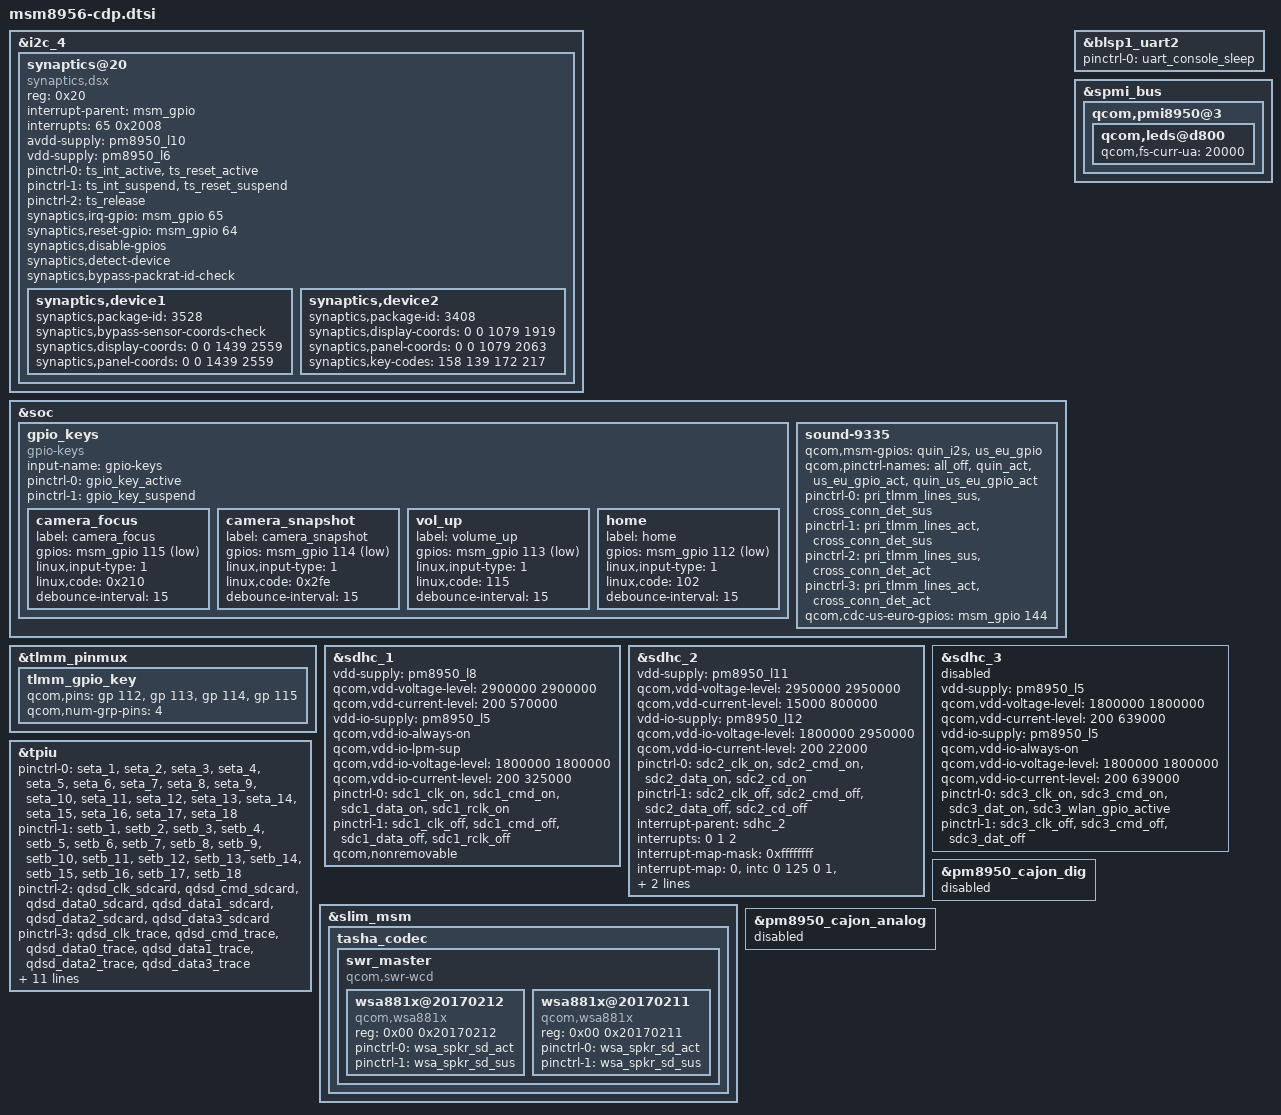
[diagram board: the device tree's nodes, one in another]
/*
 * Copyright (c) 2015, The Linux Foundation. All rights reserved.
 *
 * This program is free software; you can redistribute it and/or modify
 * it under the terms of the GNU General Public License version 2 and
 * only version 2 as published by the Free Software Foundation.
 *
 * This program is distributed in the hope that it will be useful,
 * but WITHOUT ANY WARRANTY; without even the implied warranty of
 * MERCHANTABILITY or FITNESS FOR A PARTICULAR PURPOSE.  See the
 * GNU General Public License for more details.
 */

#include "msm8976-pinctrl.dtsi"
#include "msm8976-camera-sensor-cdp.dtsi"
#include "msm8976-mdss-cdp.dtsi"
#include "msm8976-wsa881x.dtsi"

&i2c_4 { /* BLSP1 QUP4 */
	synaptics@20 {
		compatible = "synaptics,dsx";
		reg = <0x20>;
		interrupt-parent = <&msm_gpio>;
		interrupts = <65 0x2008>;
		avdd-supply = <&pm8950_l10>;
		vdd-supply = <&pm8950_l6>;
		/* pins used by touchscreen */
		pinctrl-names = "pmx_ts_active","pmx_ts_suspend","pmx_ts_release";
		pinctrl-0 = <&ts_int_active &ts_reset_active>;
		pinctrl-1 = <&ts_int_suspend &ts_reset_suspend>;
		pinctrl-2 = <&ts_release>;
		synaptics,irq-gpio = <&msm_gpio 65 0x2008>;
		synaptics,reset-gpio = <&msm_gpio 64 0x0>;
		synaptics,disable-gpios;
		synaptics,detect-device;
		synaptics,bypass-packrat-id-check;
		synaptics,device1 {
			synaptics,package-id = <3528>;
			synaptics,bypass-sensor-coords-check;
			synaptics,display-coords = <0 0 1439 2559>;
			synaptics,panel-coords = <0 0 1439 2559>;
		};
		synaptics,device2 {
			synaptics,package-id = <3408>;
			synaptics,display-coords = <0 0 1079 1919>;
			synaptics,panel-coords = <0 0 1079 2063>;
			synaptics,key-codes = <158 139 172 217>;
		};
	};
};

&soc {
	gpio_keys {
		compatible = "gpio-keys";
		input-name = "gpio-keys";
		pinctrl-names = "tlmm_gpio_key_active","tlmm_gpio_key_suspend";
		pinctrl-0 = <&gpio_key_active>;
		pinctrl-1 = <&gpio_key_suspend>;

		camera_focus {
			label = "camera_focus";
			gpios = <&msm_gpio 115 0x1>;
			linux,input-type = <1>;
			linux,code = <0x210>;
			debounce-interval = <15>;
		};

		camera_snapshot {
			label = "camera_snapshot";
			gpios = <&msm_gpio 114 0x1>;
			linux,input-type = <1>;
			linux,code = <0x2fe>;
			debounce-interval = <15>;
		};

		vol_up {
			label = "volume_up";
			gpios = <&msm_gpio 113 0x1>;
			linux,input-type = <1>;
			linux,code = <115>;
			debounce-interval = <15>;
		};

		home {
			label = "home";
			gpios = <&msm_gpio 112 0x1>;
			linux,input-type = <1>;
			linux,code = <102>;
			debounce-interval = <15>;
		};
	};

	sound-9335 {
		qcom,msm-gpios =
			"quin_i2s",
			"us_eu_gpio";
		qcom,pinctrl-names =
			"all_off",
			"quin_act",
			"us_eu_gpio_act",
			"quin_us_eu_gpio_act";
		pinctrl-names =
			"all_off",
			"quin_act",
			"us_eu_gpio_act",
			"quin_us_eu_gpio_act";
		pinctrl-0 = <&pri_tlmm_lines_sus &cross_conn_det_sus>;
		pinctrl-1 = <&pri_tlmm_lines_act &cross_conn_det_sus>;
		pinctrl-2 = <&pri_tlmm_lines_sus &cross_conn_det_act>;
		pinctrl-3 = <&pri_tlmm_lines_act &cross_conn_det_act>;
		qcom,cdc-us-euro-gpios = <&msm_gpio 144 0>;
	};
};

&tlmm_pinmux {
	tlmm_gpio_key {
		qcom,pins = <&gp 112>, <&gp 113>, <&gp 114>, <&gp 115>;
		qcom,num-grp-pins = <4>;
	};
};

&blsp1_uart2 {
	status = "ok";
	pinctrl-names = "default";
	pinctrl-0 = <&uart_console_sleep>;
};


&spmi_bus {
	qcom,pmi8950@3 {
		qcom,leds@d800 {
			qcom,fs-curr-ua = <20000>;
		};
	};
};

&sdhc_1 {
	vdd-supply = <&pm8950_l8>;
	qcom,vdd-voltage-level = <2900000 2900000>;
	qcom,vdd-current-level = <200 570000>;

	vdd-io-supply = <&pm8950_l5>;
	qcom,vdd-io-always-on;
	qcom,vdd-io-lpm-sup;
	qcom,vdd-io-voltage-level = <1800000 1800000>;
	qcom,vdd-io-current-level = <200 325000>;

	pinctrl-names = "active", "sleep";
	pinctrl-0 = <&sdc1_clk_on &sdc1_cmd_on &sdc1_data_on &sdc1_rclk_on>;
	pinctrl-1 = <&sdc1_clk_off &sdc1_cmd_off &sdc1_data_off &sdc1_rclk_off>;

	qcom,nonremovable;

	status = "ok";
};

&sdhc_2 {
	vdd-supply = <&pm8950_l11>;
	qcom,vdd-voltage-level = <2950000 2950000>;
	qcom,vdd-current-level = <15000 800000>;

	vdd-io-supply = <&pm8950_l12>;
	qcom,vdd-io-voltage-level = <1800000 2950000>;
	qcom,vdd-io-current-level = <200 22000>;

	pinctrl-names = "active", "sleep";
	pinctrl-0 = <&sdc2_clk_on &sdc2_cmd_on &sdc2_data_on &sdc2_cd_on>;
	pinctrl-1 = <&sdc2_clk_off &sdc2_cmd_off &sdc2_data_off &sdc2_cd_off>;

	#address-cells = <0>;
	interrupt-parent = <&sdhc_2>;
	interrupts = <0 1 2>;
	#interrupt-cells = <1>;
	interrupt-map-mask = <0xffffffff>;
	interrupt-map = <0 &intc 0 125 0
			1 &intc 0 221 0
			2 &msm_gpio 100 0>;
	interrupt-names = "hc_irq", "pwr_irq", "status_irq";
	cd-gpios = <&msm_gpio 100 0x1>;

	status = "ok";
};

&sdhc_3 {
	vdd-supply = <&pm8950_l5>;
	qcom,vdd-voltage-level = <1800000 1800000>;
	qcom,vdd-current-level = <200 639000>;

	vdd-io-supply = <&pm8950_l5>;
	qcom,vdd-io-always-on;
	qcom,vdd-io-voltage-level = <1800000 1800000>;
	qcom,vdd-io-current-level = <200 639000>;

	pinctrl-names = "active", "sleep";
	pinctrl-0 = <&sdc3_clk_on &sdc3_cmd_on &sdc3_dat_on
					&sdc3_wlan_gpio_active>;
	pinctrl-1 = <&sdc3_clk_off &sdc3_cmd_off &sdc3_dat_off>;

	status = "disabled";
};


/* CoreSight */
&tpiu {
	pinctrl-names = "seta-pctrl", "setb-pctrl", "sdcard", "trace",
			"swduart", "swdtrc", "jtag", "spmi";
	/* Mictor */
	pinctrl-0 = <&seta_1 &seta_2 &seta_3 &seta_4 &seta_5 &seta_6 &seta_7
		     &seta_8 &seta_9 &seta_10 &seta_11 &seta_12 &seta_13
		     &seta_14 &seta_15 &seta_16 &seta_17 &seta_18>;
	pinctrl-1 = <&setb_1 &setb_2 &setb_3 &setb_4 &setb_5 &setb_6 &setb_7
		     &setb_8 &setb_9 &setb_10 &setb_11 &setb_12 &setb_13
		     &setb_14 &setb_15 &setb_16 &setb_17 &setb_18>;
	/* NIDnT */
	pinctrl-2 = <&qdsd_clk_sdcard &qdsd_cmd_sdcard
		    &qdsd_data0_sdcard &qdsd_data1_sdcard
		    &qdsd_data2_sdcard &qdsd_data3_sdcard>;
	pinctrl-3 = <&qdsd_clk_trace &qdsd_cmd_trace
		    &qdsd_data0_trace &qdsd_data1_trace
		    &qdsd_data2_trace &qdsd_data3_trace>;
	pinctrl-4 = <&qdsd_cmd_swduart &qdsd_data0_swduart
		    &qdsd_data1_swduart &qdsd_data2_swduart
		    &qdsd_data3_swduart>;
	pinctrl-5 = <&qdsd_clk_swdtrc &qdsd_cmd_swdtrc
		    &qdsd_data0_swdtrc &qdsd_data1_swdtrc
		    &qdsd_data2_swdtrc &qdsd_data3_swdtrc>;
	pinctrl-6 = <&qdsd_cmd_jtag &qdsd_data0_jtag
		    &qdsd_data1_jtag &qdsd_data2_jtag
		    &qdsd_data3_jtag>;
	pinctrl-7 = <&qdsd_clk_spmi &qdsd_cmd_spmi
		    &qdsd_data0_spmi &qdsd_data3_spmi>;
};

&slim_msm {
	tasha_codec {
		swr_master {
			compatible = "qcom,swr-wcd";
			#address-cells = <2>;
			#size-cells = <0>;
			wsa881x@20170212 {
				compatible = "qcom,wsa881x";
				reg = <0x00 0x20170212>;
				pinctrl-names = "wsa_spkr_sd_act",
						"wsa_spkr_sd_sus";
				pinctrl-0 = <&wsa_spkr_sd_act>;
				pinctrl-1 = <&wsa_spkr_sd_sus>;
			};

			wsa881x@20170211 {
				compatible = "qcom,wsa881x";
				reg = <0x00 0x20170211>;
				pinctrl-names = "wsa_spkr_sd_act",
						"wsa_spkr_sd_sus";
				pinctrl-0 = <&wsa_spkr_sd_act>;
				pinctrl-1 = <&wsa_spkr_sd_sus>;
			};
		};
	};
};

&pm8950_cajon_dig {
	status = "disabled";
};

&pm8950_cajon_analog {
	status = "disabled";
};
